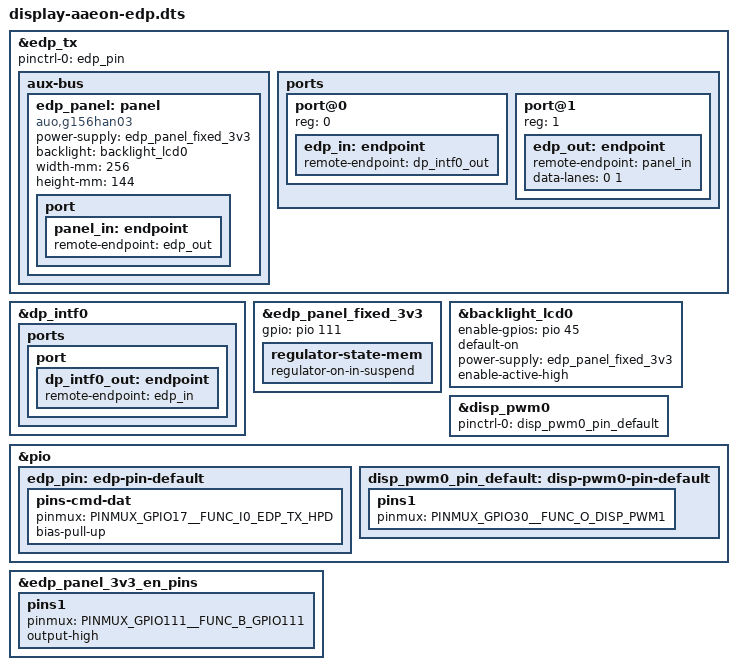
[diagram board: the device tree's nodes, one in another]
/dts-v1/;
/plugin/;

#include <dt-bindings/pinctrl/mediatek,mt8188-pinfunc.h>
#include <dt-bindings/gpio/gpio.h>

/ {
	fragment@0 {
		target = <&edp_tx>;
		__overlay__ {
			pinctrl-names = "default";
			pinctrl-0 = <&edp_pin>;
			status = "okay";

			aux-bus {
				edp_panel: panel {
                    /*
                     * Temporary compatibility for bring-up.
                     * Replace with proper G116HAN01.0
                     * panel support later.
                     */
					compatible = "auo,g156han03";
					power-supply = <&edp_panel_fixed_3v3>;
					backlight = <&backlight_lcd0>;
					width-mm = <256>;
                    height-mm = <144>;
					status = "okay";

					port {
						panel_in: endpoint {
							remote-endpoint = <&edp_out>;
						};
					};
				};
			};

			ports {
				#address-cells = <1>;
				#size-cells = <0>;

				port@0 {
					reg = <0>;
					edp_in: endpoint {
						remote-endpoint = <&dp_intf0_out>;
					};
				};

				port@1 {
					reg = <1>;
					edp_out: endpoint {
						remote-endpoint = <&panel_in>;
						data-lanes = <0 1>;
					};
				};
			};
		};
	};

	fragment@1 {
		target = <&dp_intf0>;
		__overlay__ {
			status = "okay";
			ports {
				port {
					dp_intf0_out: endpoint {
						remote-endpoint = <&edp_in>;
					};
				};
			};
		};
	};

	fragment@3 {
		target = <&edp_panel_fixed_3v3>;
		__overlay__ {
            gpio = <&pio 111 GPIO_ACTIVE_HIGH>;
			regulator-state-mem {
				regulator-on-in-suspend;
			};
		};
	};

	fragment@4 {
		target = <&backlight_lcd0>;
		__overlay__ {
            enable-gpios = <&pio 45 GPIO_ACTIVE_HIGH>;
			default-on;
			power-supply = <&edp_panel_fixed_3v3>;
			enable-active-high;
			status = "okay";
		};
	};

	fragment@5 {
		target = <&disp_pwm0>;
		__overlay__ {
			status = "okay";
			pinctrl-names = "default";
			pinctrl-0 = <&disp_pwm0_pin_default>;
		};
	};

	fragment@6 {
		target = <&pio>;
		__overlay__ {
			edp_pin: edp-pin-default {
				pins-cmd-dat {
					pinmux = <PINMUX_GPIO17__FUNC_I0_EDP_TX_HPD>;
					bias-pull-up;
				};
			};

			disp_pwm0_pin_default: disp-pwm0-pin-default {
				pins1 {
					pinmux = <PINMUX_GPIO30__FUNC_O_DISP_PWM1>;
				};
			};
		};
	};

    fragment@7 {
        target = <&edp_panel_3v3_en_pins>;
        __overlay__ {
            pins1 {
                pinmux = <PINMUX_GPIO111__FUNC_B_GPIO111>;
                output-high;
            };
        };
    };
};
